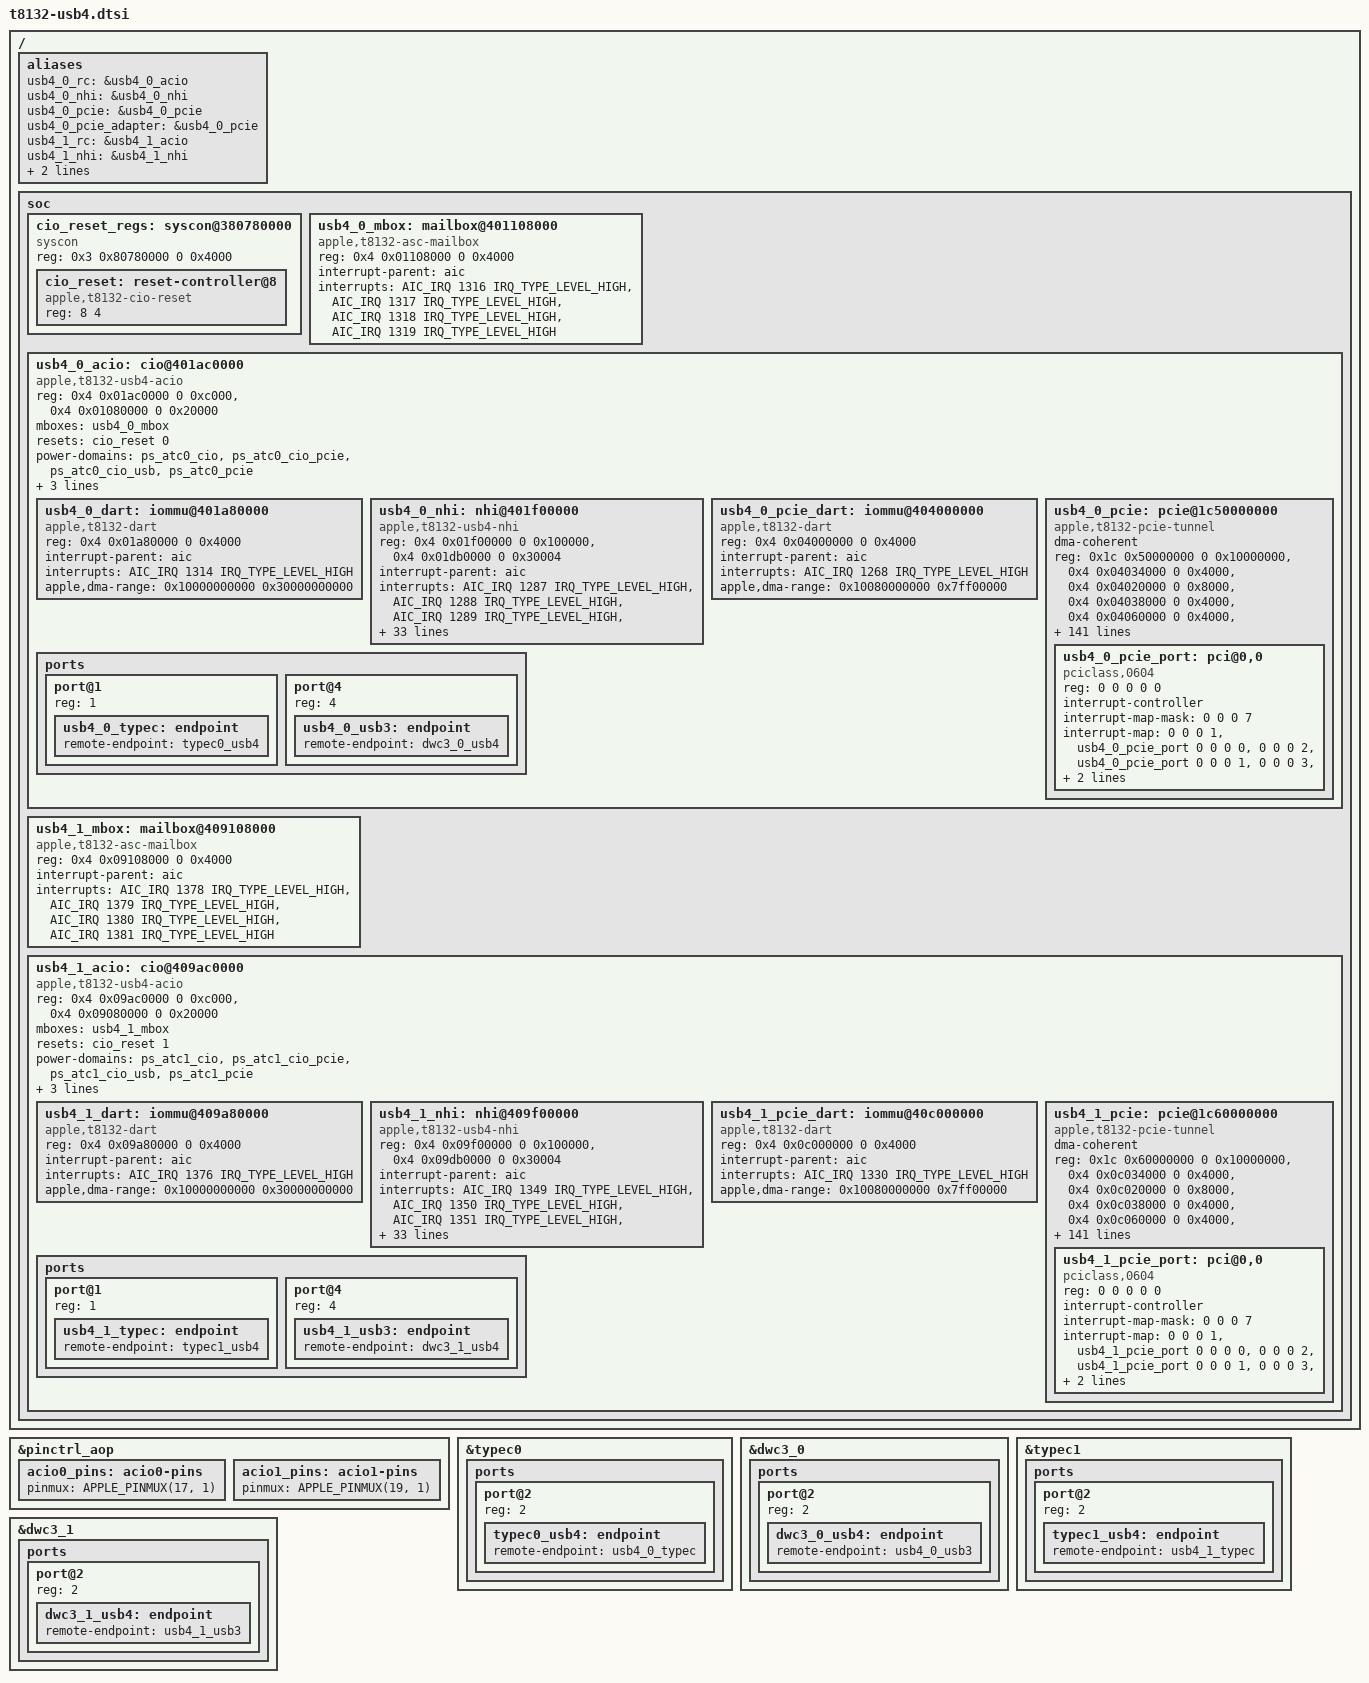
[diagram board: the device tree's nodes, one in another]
// SPDX-License-Identifier: GPL-2.0+ OR MIT
/*
 * T8132 USB4/Thunderbolt on ACIO0 and ACIO1, the Type-C ports that J713 and J773g share.
 * Resources from the J773g and J713 ADTs, which agree for both controllers.
 */
/ {
	aliases {
		usb4_0_rc = &usb4_0_acio;
		usb4_0_nhi = &usb4_0_nhi;
		usb4_0_pcie = &usb4_0_pcie;
		usb4_0_pcie_adapter = &usb4_0_pcie;
		usb4_1_rc = &usb4_1_acio;
		usb4_1_nhi = &usb4_1_nhi;
		usb4_1_pcie = &usb4_1_pcie;
		usb4_1_pcie_adapter = &usb4_1_pcie;
	};
	soc {
		cio_reset_regs: syscon@380780000 {
			compatible = "syscon", "simple-mfd";
			reg = <0x3 0x80780000 0 0x4000>;
			#address-cells = <1>;
			#size-cells = <1>;
			cio_reset: reset-controller@8 {
				compatible = "apple,t8132-cio-reset", "apple,t6000-cio-reset";
				reg = <8 4>;
				#reset-cells = <1>;
			};
		};
		usb4_0_mbox: mailbox@401108000 {
			compatible = "apple,t8132-asc-mailbox", "apple,asc-mailbox-v4";
			reg = <0x4 0x01108000 0 0x4000>;
			interrupt-parent = <&aic>;
			/* ADT orders each pair as not-empty, empty. */
			interrupts = <AIC_IRQ 1316 IRQ_TYPE_LEVEL_HIGH>,
				     <AIC_IRQ 1317 IRQ_TYPE_LEVEL_HIGH>,
				     <AIC_IRQ 1318 IRQ_TYPE_LEVEL_HIGH>,
				     <AIC_IRQ 1319 IRQ_TYPE_LEVEL_HIGH>;
			interrupt-names = "send-empty",
				"send-not-empty",
				"recv-empty",
				"recv-not-empty";
			#mbox-cells = <0>;
		};
		usb4_0_acio: cio@401ac0000 {
			compatible = "apple,t8132-usb4-acio", "apple,t8103-usb4-acio";
			reg = <0x4 0x01ac0000 0 0xc000>, <0x4 0x01080000 0 0x20000>;
			reg-names = "rc", "sram";
			mboxes = <&usb4_0_mbox>;
			resets = <&cio_reset 0>;
			power-domains = <&ps_atc0_cio>, <&ps_atc0_cio_pcie>,
					<&ps_atc0_cio_usb>, <&ps_atc0_pcie>;
			/* The port controller hands over USB4/TBT mode and cable details. */
			thunderbolt-switch;
			pinctrl-0 = <&acio0_pins>;
			pinctrl-names = "default";
			/* PCIe windows lie outside ACIO's local register aperture. */
			#address-cells = <2>;
			#size-cells = <2>;
			ranges;
			nonposted-mmio;
			usb4_0_dart: iommu@401a80000 {
				compatible = "apple,t8132-dart", "apple,t8110-dart";
				reg = <0x4 0x01a80000 0 0x4000>;
				interrupt-parent = <&aic>;
				interrupts = <AIC_IRQ 1314 IRQ_TYPE_LEVEL_HIGH>;
				#iommu-cells = <1>;
				apple,dma-range = /bits/ 64 <0x10000000000 0x30000000000>;
			};
			usb4_0_nhi: nhi@401f00000 {
				compatible = "apple,t8132-usb4-nhi", "apple,t8103-usb4-nhi";
				reg = <0x4 0x01f00000 0 0x100000>,
				      <0x4 0x01db0000 0 0x30004>;
				reg-names = "nhi", "pdf";
				interrupt-parent = <&aic>;
				interrupts = <AIC_IRQ 1287 IRQ_TYPE_LEVEL_HIGH>,
					<AIC_IRQ 1288 IRQ_TYPE_LEVEL_HIGH>,
					<AIC_IRQ 1289 IRQ_TYPE_LEVEL_HIGH>,
					<AIC_IRQ 1290 IRQ_TYPE_LEVEL_HIGH>,
					<AIC_IRQ 1291 IRQ_TYPE_LEVEL_HIGH>,
					<AIC_IRQ 1292 IRQ_TYPE_LEVEL_HIGH>,
					<AIC_IRQ 1293 IRQ_TYPE_LEVEL_HIGH>,
					<AIC_IRQ 1294 IRQ_TYPE_LEVEL_HIGH>,
					<AIC_IRQ 1295 IRQ_TYPE_LEVEL_HIGH>,
					<AIC_IRQ 1296 IRQ_TYPE_LEVEL_HIGH>,
					<AIC_IRQ 1297 IRQ_TYPE_LEVEL_HIGH>,
					<AIC_IRQ 1298 IRQ_TYPE_LEVEL_HIGH>,
					<AIC_IRQ 1299 IRQ_TYPE_LEVEL_HIGH>,
					<AIC_IRQ 1300 IRQ_TYPE_LEVEL_HIGH>,
					<AIC_IRQ 1301 IRQ_TYPE_LEVEL_HIGH>,
					<AIC_IRQ 1302 IRQ_TYPE_LEVEL_HIGH>,
					<AIC_IRQ 1303 IRQ_TYPE_LEVEL_HIGH>,
					<AIC_IRQ 1304 IRQ_TYPE_LEVEL_HIGH>,
					<AIC_IRQ 1305 IRQ_TYPE_LEVEL_HIGH>,
					<AIC_IRQ 1306 IRQ_TYPE_LEVEL_HIGH>,
					<AIC_IRQ 1307 IRQ_TYPE_LEVEL_HIGH>,
					<AIC_IRQ 1308 IRQ_TYPE_LEVEL_HIGH>,
					<AIC_IRQ 1309 IRQ_TYPE_LEVEL_HIGH>,
					<AIC_IRQ 1310 IRQ_TYPE_LEVEL_HIGH>;
				interrupt-names = "txring0",
					"txring1",
					"txring2",
					"txring3",
					"txring4",
					"txring5",
					"txring6",
					"txring7",
					"txring8",
					"txring9",
					"txring10",
					"txring11",
					"rxring0",
					"rxring1",
					"rxring2",
					"rxring3",
					"rxring4",
					"rxring5",
					"rxring6",
					"rxring7",
					"rxring8",
					"rxring9",
					"rxring10",
					"rxring11";
				/* T8132 has a DART stream for each TX and RX ring. */
				iommus = <&usb4_0_dart 0>,
				<&usb4_0_dart 1>,
				<&usb4_0_dart 2>,
				<&usb4_0_dart 3>,
				<&usb4_0_dart 4>,
				<&usb4_0_dart 5>,
				<&usb4_0_dart 6>,
				<&usb4_0_dart 7>,
				<&usb4_0_dart 8>,
				<&usb4_0_dart 9>,
				<&usb4_0_dart 10>,
				<&usb4_0_dart 11>,
				<&usb4_0_dart 16>,
				<&usb4_0_dart 17>,
				<&usb4_0_dart 18>,
				<&usb4_0_dart 19>,
				<&usb4_0_dart 20>,
				<&usb4_0_dart 21>,
				<&usb4_0_dart 22>,
				<&usb4_0_dart 23>,
				<&usb4_0_dart 24>,
				<&usb4_0_dart 25>,
				<&usb4_0_dart 26>,
				<&usb4_0_dart 27>;
				apple,thunderbolt-drom = [00];
			};
			usb4_0_pcie_dart: iommu@404000000 {
				compatible = "apple,t8132-dart", "apple,t8110-dart";
				reg = <0x4 0x04000000 0 0x4000>;
				interrupt-parent = <&aic>;
				interrupts = <AIC_IRQ 1268 IRQ_TYPE_LEVEL_HIGH>;
				#iommu-cells = <1>;
				apple,dma-range = /bits/ 64 <0x10080000000 0x7ff00000>;
			};
			usb4_0_pcie: pcie@1c50000000 {
				compatible = "apple,t8132-pcie-tunnel";
				dma-coherent;
				device_type = "pci";
				reg = <0x1c 0x50000000 0 0x10000000>,
				      <0x4 0x04034000 0 0x4000>,
				      <0x4 0x04020000 0 0x8000>,
				      <0x4 0x04038000 0 0x4000>,
				      <0x4 0x04060000 0 0x4000>,
				      <0x4 0x01e44000 0 0x4000>,
				      <0x4 0x0402c000 0 0x4000>,
				      <0x4 0x04028000 0 0x4000>;
				reg-names = "config",
					"rc",
					"port0",
					"fabric",
					"debug",
					"adapter",
					"ltssm",
					"intr2axi";
				interrupt-parent = <&aic>;
				interrupts = <AIC_IRQ 1267 IRQ_TYPE_LEVEL_HIGH>;
				msi-controller;
				msi-parent = <&usb4_0_pcie>;
				msi-ranges = <&aic AIC_IRQ 1570 IRQ_TYPE_EDGE_RISING 32>;
				apple,msi-vector-base = <64>;
				/*
				 * Give each PCI bus its own DART stream. Keep functions on
				 * the same bus together, as on the other Apple PCIe hosts.
				 * Cover the full bus-range so hotplug bus renumbering does
				 * not alias unrelated buses. PCI ACS and DMA aliases still
				 * determine which streams may use independent domains.
				 */
				iommu-map-mask = <0xff00>;
				iommu-map = <0x0000 &usb4_0_pcie_dart 0 1>,
					    <0x0100 &usb4_0_pcie_dart 1 1>,
					    <0x0200 &usb4_0_pcie_dart 2 1>,
					    <0x0300 &usb4_0_pcie_dart 3 1>,
					    <0x0400 &usb4_0_pcie_dart 4 1>,
					    <0x0500 &usb4_0_pcie_dart 5 1>,
					    <0x0600 &usb4_0_pcie_dart 6 1>,
					    <0x0700 &usb4_0_pcie_dart 7 1>,
					    <0x0800 &usb4_0_pcie_dart 8 1>,
					    <0x0900 &usb4_0_pcie_dart 9 1>,
					    <0x0a00 &usb4_0_pcie_dart 10 1>,
					    <0x0b00 &usb4_0_pcie_dart 11 1>,
					    <0x0c00 &usb4_0_pcie_dart 12 1>,
					    <0x0d00 &usb4_0_pcie_dart 13 1>,
					    <0x0e00 &usb4_0_pcie_dart 14 1>,
					    <0x0f00 &usb4_0_pcie_dart 15 1>,
					    <0x1000 &usb4_0_pcie_dart 16 1>,
					    <0x1100 &usb4_0_pcie_dart 17 1>,
					    <0x1200 &usb4_0_pcie_dart 18 1>,
					    <0x1300 &usb4_0_pcie_dart 19 1>,
					    <0x1400 &usb4_0_pcie_dart 20 1>,
					    <0x1500 &usb4_0_pcie_dart 21 1>,
					    <0x1600 &usb4_0_pcie_dart 22 1>,
					    <0x1700 &usb4_0_pcie_dart 23 1>,
					    <0x1800 &usb4_0_pcie_dart 24 1>,
					    <0x1900 &usb4_0_pcie_dart 25 1>,
					    <0x1a00 &usb4_0_pcie_dart 26 1>,
					    <0x1b00 &usb4_0_pcie_dart 27 1>,
					    <0x1c00 &usb4_0_pcie_dart 28 1>,
					    <0x1d00 &usb4_0_pcie_dart 29 1>,
					    <0x1e00 &usb4_0_pcie_dart 30 1>,
					    <0x1f00 &usb4_0_pcie_dart 31 1>,
					    <0x2000 &usb4_0_pcie_dart 32 1>,
					    <0x2100 &usb4_0_pcie_dart 33 1>,
					    <0x2200 &usb4_0_pcie_dart 34 1>,
					    <0x2300 &usb4_0_pcie_dart 35 1>,
					    <0x2400 &usb4_0_pcie_dart 36 1>,
					    <0x2500 &usb4_0_pcie_dart 37 1>,
					    <0x2600 &usb4_0_pcie_dart 38 1>,
					    <0x2700 &usb4_0_pcie_dart 39 1>,
					    <0x2800 &usb4_0_pcie_dart 40 1>,
					    <0x2900 &usb4_0_pcie_dart 41 1>,
					    <0x2a00 &usb4_0_pcie_dart 42 1>,
					    <0x2b00 &usb4_0_pcie_dart 43 1>,
					    <0x2c00 &usb4_0_pcie_dart 44 1>,
					    <0x2d00 &usb4_0_pcie_dart 45 1>,
					    <0x2e00 &usb4_0_pcie_dart 46 1>,
					    <0x2f00 &usb4_0_pcie_dart 47 1>,
					    <0x3000 &usb4_0_pcie_dart 48 1>,
					    <0x3100 &usb4_0_pcie_dart 49 1>,
					    <0x3200 &usb4_0_pcie_dart 50 1>,
					    <0x3300 &usb4_0_pcie_dart 51 1>,
					    <0x3400 &usb4_0_pcie_dart 52 1>,
					    <0x3500 &usb4_0_pcie_dart 53 1>,
					    <0x3600 &usb4_0_pcie_dart 54 1>,
					    <0x3700 &usb4_0_pcie_dart 55 1>,
					    <0x3800 &usb4_0_pcie_dart 56 1>,
					    <0x3900 &usb4_0_pcie_dart 57 1>,
					    <0x3a00 &usb4_0_pcie_dart 58 1>,
					    <0x3b00 &usb4_0_pcie_dart 59 1>,
					    <0x3c00 &usb4_0_pcie_dart 60 1>,
					    <0x3d00 &usb4_0_pcie_dart 61 1>,
					    <0x3e00 &usb4_0_pcie_dart 62 1>,
					    <0x3f00 &usb4_0_pcie_dart 63 1>,
					    <0x4000 &usb4_0_pcie_dart 64 1>,
					    <0x4100 &usb4_0_pcie_dart 65 1>,
					    <0x4200 &usb4_0_pcie_dart 66 1>,
					    <0x4300 &usb4_0_pcie_dart 67 1>,
					    <0x4400 &usb4_0_pcie_dart 68 1>,
					    <0x4500 &usb4_0_pcie_dart 69 1>,
					    <0x4600 &usb4_0_pcie_dart 70 1>,
					    <0x4700 &usb4_0_pcie_dart 71 1>,
					    <0x4800 &usb4_0_pcie_dart 72 1>,
					    <0x4900 &usb4_0_pcie_dart 73 1>,
					    <0x4a00 &usb4_0_pcie_dart 74 1>,
					    <0x4b00 &usb4_0_pcie_dart 75 1>,
					    <0x4c00 &usb4_0_pcie_dart 76 1>,
					    <0x4d00 &usb4_0_pcie_dart 77 1>,
					    <0x4e00 &usb4_0_pcie_dart 78 1>,
					    <0x4f00 &usb4_0_pcie_dart 79 1>,
					    <0x5000 &usb4_0_pcie_dart 80 1>,
					    <0x5100 &usb4_0_pcie_dart 81 1>,
					    <0x5200 &usb4_0_pcie_dart 82 1>,
					    <0x5300 &usb4_0_pcie_dart 83 1>,
					    <0x5400 &usb4_0_pcie_dart 84 1>,
					    <0x5500 &usb4_0_pcie_dart 85 1>,
					    <0x5600 &usb4_0_pcie_dart 86 1>,
					    <0x5700 &usb4_0_pcie_dart 87 1>,
					    <0x5800 &usb4_0_pcie_dart 88 1>,
					    <0x5900 &usb4_0_pcie_dart 89 1>,
					    <0x5a00 &usb4_0_pcie_dart 90 1>,
					    <0x5b00 &usb4_0_pcie_dart 91 1>,
					    <0x5c00 &usb4_0_pcie_dart 92 1>,
					    <0x5d00 &usb4_0_pcie_dart 93 1>,
					    <0x5e00 &usb4_0_pcie_dart 94 1>,
					    <0x5f00 &usb4_0_pcie_dart 95 1>,
					    <0x6000 &usb4_0_pcie_dart 96 1>,
					    <0x6100 &usb4_0_pcie_dart 97 1>,
					    <0x6200 &usb4_0_pcie_dart 98 1>,
					    <0x6300 &usb4_0_pcie_dart 99 1>,
					    <0x6400 &usb4_0_pcie_dart 100 1>,
					    <0x6500 &usb4_0_pcie_dart 101 1>,
					    <0x6600 &usb4_0_pcie_dart 102 1>,
					    <0x6700 &usb4_0_pcie_dart 103 1>,
					    <0x6800 &usb4_0_pcie_dart 104 1>,
					    <0x6900 &usb4_0_pcie_dart 105 1>,
					    <0x6a00 &usb4_0_pcie_dart 106 1>,
					    <0x6b00 &usb4_0_pcie_dart 107 1>,
					    <0x6c00 &usb4_0_pcie_dart 108 1>,
					    <0x6d00 &usb4_0_pcie_dart 109 1>,
					    <0x6e00 &usb4_0_pcie_dart 110 1>,
					    <0x6f00 &usb4_0_pcie_dart 111 1>,
					    <0x7000 &usb4_0_pcie_dart 112 1>,
					    <0x7100 &usb4_0_pcie_dart 113 1>,
					    <0x7200 &usb4_0_pcie_dart 114 1>,
					    <0x7300 &usb4_0_pcie_dart 115 1>,
					    <0x7400 &usb4_0_pcie_dart 116 1>,
					    <0x7500 &usb4_0_pcie_dart 117 1>,
					    <0x7600 &usb4_0_pcie_dart 118 1>,
					    <0x7700 &usb4_0_pcie_dart 119 1>,
					    <0x7800 &usb4_0_pcie_dart 120 1>,
					    <0x7900 &usb4_0_pcie_dart 121 1>,
					    <0x7a00 &usb4_0_pcie_dart 122 1>,
					    <0x7b00 &usb4_0_pcie_dart 123 1>,
					    <0x7c00 &usb4_0_pcie_dart 124 1>,
					    <0x7d00 &usb4_0_pcie_dart 125 1>,
					    <0x7e00 &usb4_0_pcie_dart 126 1>,
					    <0x7f00 &usb4_0_pcie_dart 127 1>;
				linux,pci-domain = <1>;
				bus-range = <0 127>;
				#address-cells = <3>;
				#size-cells = <2>;
				ranges = <0x43000000 0x8 0 0x8 0 0x2 0>,
					 <0x02000000 0 0x100000 0xa 0x00100000 0 0x3ff00000>;
				usb4_0_pcie_port: pci@0,0 {
					compatible = "pciclass,0604";
					device_type = "pci";
					reg = <0 0 0 0 0>;
					#address-cells = <3>;
					#size-cells = <2>;
					ranges;
					interrupt-controller;
					#interrupt-cells = <1>;
					interrupt-map-mask = <0 0 0 7>;
					interrupt-map = <0 0 0 1 &usb4_0_pcie_port 0 0 0 0>,
							<0 0 0 2 &usb4_0_pcie_port 0 0 0 1>,
							<0 0 0 3 &usb4_0_pcie_port 0 0 0 2>,
							<0 0 0 4 &usb4_0_pcie_port 0 0 0 3>;
				};
			};
			ports {
				#address-cells = <1>;
				#size-cells = <0>;
				port@1 {
					reg = <1>;
					usb4_0_typec: endpoint { remote-endpoint = <&typec0_usb4>; };
				};
				port@4 {
					reg = <4>;
					usb4_0_usb3: endpoint { remote-endpoint = <&dwc3_0_usb4>; };
				};
			};
		};
		usb4_1_mbox: mailbox@409108000 {
			compatible = "apple,t8132-asc-mailbox", "apple,asc-mailbox-v4";
			reg = <0x4 0x09108000 0 0x4000>;
			interrupt-parent = <&aic>;
			/* ADT orders each pair as not-empty, empty. */
			interrupts = <AIC_IRQ 1378 IRQ_TYPE_LEVEL_HIGH>,
				     <AIC_IRQ 1379 IRQ_TYPE_LEVEL_HIGH>,
				     <AIC_IRQ 1380 IRQ_TYPE_LEVEL_HIGH>,
				     <AIC_IRQ 1381 IRQ_TYPE_LEVEL_HIGH>;
			interrupt-names = "send-empty",
				"send-not-empty",
				"recv-empty",
				"recv-not-empty";
			#mbox-cells = <0>;
		};
		usb4_1_acio: cio@409ac0000 {
			compatible = "apple,t8132-usb4-acio", "apple,t8103-usb4-acio";
			reg = <0x4 0x09ac0000 0 0xc000>, <0x4 0x09080000 0 0x20000>;
			reg-names = "rc", "sram";
			mboxes = <&usb4_1_mbox>;
			resets = <&cio_reset 1>;
			power-domains = <&ps_atc1_cio>, <&ps_atc1_cio_pcie>,
					<&ps_atc1_cio_usb>, <&ps_atc1_pcie>;
			/* The port controller hands over USB4/TBT mode and cable details. */
			thunderbolt-switch;
			pinctrl-0 = <&acio1_pins>;
			pinctrl-names = "default";
			/* PCIe windows lie outside ACIO's local register aperture. */
			#address-cells = <2>;
			#size-cells = <2>;
			ranges;
			nonposted-mmio;
			usb4_1_dart: iommu@409a80000 {
				compatible = "apple,t8132-dart", "apple,t8110-dart";
				reg = <0x4 0x09a80000 0 0x4000>;
				interrupt-parent = <&aic>;
				interrupts = <AIC_IRQ 1376 IRQ_TYPE_LEVEL_HIGH>;
				#iommu-cells = <1>;
				apple,dma-range = /bits/ 64 <0x10000000000 0x30000000000>;
			};
			usb4_1_nhi: nhi@409f00000 {
				compatible = "apple,t8132-usb4-nhi", "apple,t8103-usb4-nhi";
				reg = <0x4 0x09f00000 0 0x100000>,
				      <0x4 0x09db0000 0 0x30004>;
				reg-names = "nhi", "pdf";
				interrupt-parent = <&aic>;
				interrupts = <AIC_IRQ 1349 IRQ_TYPE_LEVEL_HIGH>,
					<AIC_IRQ 1350 IRQ_TYPE_LEVEL_HIGH>,
					<AIC_IRQ 1351 IRQ_TYPE_LEVEL_HIGH>,
					<AIC_IRQ 1352 IRQ_TYPE_LEVEL_HIGH>,
					<AIC_IRQ 1353 IRQ_TYPE_LEVEL_HIGH>,
					<AIC_IRQ 1354 IRQ_TYPE_LEVEL_HIGH>,
					<AIC_IRQ 1355 IRQ_TYPE_LEVEL_HIGH>,
					<AIC_IRQ 1356 IRQ_TYPE_LEVEL_HIGH>,
					<AIC_IRQ 1357 IRQ_TYPE_LEVEL_HIGH>,
					<AIC_IRQ 1358 IRQ_TYPE_LEVEL_HIGH>,
					<AIC_IRQ 1359 IRQ_TYPE_LEVEL_HIGH>,
					<AIC_IRQ 1360 IRQ_TYPE_LEVEL_HIGH>,
					<AIC_IRQ 1361 IRQ_TYPE_LEVEL_HIGH>,
					<AIC_IRQ 1362 IRQ_TYPE_LEVEL_HIGH>,
					<AIC_IRQ 1363 IRQ_TYPE_LEVEL_HIGH>,
					<AIC_IRQ 1364 IRQ_TYPE_LEVEL_HIGH>,
					<AIC_IRQ 1365 IRQ_TYPE_LEVEL_HIGH>,
					<AIC_IRQ 1366 IRQ_TYPE_LEVEL_HIGH>,
					<AIC_IRQ 1367 IRQ_TYPE_LEVEL_HIGH>,
					<AIC_IRQ 1368 IRQ_TYPE_LEVEL_HIGH>,
					<AIC_IRQ 1369 IRQ_TYPE_LEVEL_HIGH>,
					<AIC_IRQ 1370 IRQ_TYPE_LEVEL_HIGH>,
					<AIC_IRQ 1371 IRQ_TYPE_LEVEL_HIGH>,
					<AIC_IRQ 1372 IRQ_TYPE_LEVEL_HIGH>;
				interrupt-names = "txring0",
					"txring1",
					"txring2",
					"txring3",
					"txring4",
					"txring5",
					"txring6",
					"txring7",
					"txring8",
					"txring9",
					"txring10",
					"txring11",
					"rxring0",
					"rxring1",
					"rxring2",
					"rxring3",
					"rxring4",
					"rxring5",
					"rxring6",
					"rxring7",
					"rxring8",
					"rxring9",
					"rxring10",
					"rxring11";
				/* T8132 has a DART stream for each TX and RX ring. */
				iommus = <&usb4_1_dart 0>,
				<&usb4_1_dart 1>,
				<&usb4_1_dart 2>,
				<&usb4_1_dart 3>,
				<&usb4_1_dart 4>,
				<&usb4_1_dart 5>,
				<&usb4_1_dart 6>,
				<&usb4_1_dart 7>,
				<&usb4_1_dart 8>,
				<&usb4_1_dart 9>,
				<&usb4_1_dart 10>,
				<&usb4_1_dart 11>,
				<&usb4_1_dart 16>,
				<&usb4_1_dart 17>,
				<&usb4_1_dart 18>,
				<&usb4_1_dart 19>,
				<&usb4_1_dart 20>,
				<&usb4_1_dart 21>,
				<&usb4_1_dart 22>,
				<&usb4_1_dart 23>,
				<&usb4_1_dart 24>,
				<&usb4_1_dart 25>,
				<&usb4_1_dart 26>,
				<&usb4_1_dart 27>;
				apple,thunderbolt-drom = [00];
			};
			usb4_1_pcie_dart: iommu@40c000000 {
				compatible = "apple,t8132-dart", "apple,t8110-dart";
				reg = <0x4 0x0c000000 0 0x4000>;
				interrupt-parent = <&aic>;
				interrupts = <AIC_IRQ 1330 IRQ_TYPE_LEVEL_HIGH>;
				#iommu-cells = <1>;
				apple,dma-range = /bits/ 64 <0x10080000000 0x7ff00000>;
			};
			usb4_1_pcie: pcie@1c60000000 {
				compatible = "apple,t8132-pcie-tunnel";
				dma-coherent;
				device_type = "pci";
				reg = <0x1c 0x60000000 0 0x10000000>,
				      <0x4 0x0c034000 0 0x4000>,
				      <0x4 0x0c020000 0 0x8000>,
				      <0x4 0x0c038000 0 0x4000>,
				      <0x4 0x0c060000 0 0x4000>,
				      <0x4 0x09e44000 0 0x4000>,
				      <0x4 0x0c02c000 0 0x4000>,
				      <0x4 0x0c028000 0 0x4000>;
				reg-names = "config",
					"rc",
					"port0",
					"fabric",
					"debug",
					"adapter",
					"ltssm",
					"intr2axi";
				interrupt-parent = <&aic>;
				interrupts = <AIC_IRQ 1329 IRQ_TYPE_LEVEL_HIGH>;
				msi-controller;
				msi-parent = <&usb4_1_pcie>;
				msi-ranges = <&aic AIC_IRQ 1634 IRQ_TYPE_EDGE_RISING 32>;
				apple,msi-vector-base = <128>;
				/*
				 * Give each PCI bus its own DART stream. Keep functions on
				 * the same bus together, as on the other Apple PCIe hosts.
				 * Cover the full bus-range so hotplug bus renumbering does
				 * not alias unrelated buses. PCI ACS and DMA aliases still
				 * determine which streams may use independent domains.
				 */
				iommu-map-mask = <0xff00>;
				iommu-map = <0x0000 &usb4_1_pcie_dart 0 1>,
					    <0x0100 &usb4_1_pcie_dart 1 1>,
					    <0x0200 &usb4_1_pcie_dart 2 1>,
					    <0x0300 &usb4_1_pcie_dart 3 1>,
					    <0x0400 &usb4_1_pcie_dart 4 1>,
					    <0x0500 &usb4_1_pcie_dart 5 1>,
					    <0x0600 &usb4_1_pcie_dart 6 1>,
					    <0x0700 &usb4_1_pcie_dart 7 1>,
					    <0x0800 &usb4_1_pcie_dart 8 1>,
					    <0x0900 &usb4_1_pcie_dart 9 1>,
					    <0x0a00 &usb4_1_pcie_dart 10 1>,
					    <0x0b00 &usb4_1_pcie_dart 11 1>,
					    <0x0c00 &usb4_1_pcie_dart 12 1>,
					    <0x0d00 &usb4_1_pcie_dart 13 1>,
					    <0x0e00 &usb4_1_pcie_dart 14 1>,
					    <0x0f00 &usb4_1_pcie_dart 15 1>,
					    <0x1000 &usb4_1_pcie_dart 16 1>,
					    <0x1100 &usb4_1_pcie_dart 17 1>,
					    <0x1200 &usb4_1_pcie_dart 18 1>,
					    <0x1300 &usb4_1_pcie_dart 19 1>,
					    <0x1400 &usb4_1_pcie_dart 20 1>,
					    <0x1500 &usb4_1_pcie_dart 21 1>,
					    <0x1600 &usb4_1_pcie_dart 22 1>,
					    <0x1700 &usb4_1_pcie_dart 23 1>,
					    <0x1800 &usb4_1_pcie_dart 24 1>,
					    <0x1900 &usb4_1_pcie_dart 25 1>,
					    <0x1a00 &usb4_1_pcie_dart 26 1>,
					    <0x1b00 &usb4_1_pcie_dart 27 1>,
					    <0x1c00 &usb4_1_pcie_dart 28 1>,
					    <0x1d00 &usb4_1_pcie_dart 29 1>,
					    <0x1e00 &usb4_1_pcie_dart 30 1>,
					    <0x1f00 &usb4_1_pcie_dart 31 1>,
					    <0x2000 &usb4_1_pcie_dart 32 1>,
					    <0x2100 &usb4_1_pcie_dart 33 1>,
					    <0x2200 &usb4_1_pcie_dart 34 1>,
					    <0x2300 &usb4_1_pcie_dart 35 1>,
					    <0x2400 &usb4_1_pcie_dart 36 1>,
					    <0x2500 &usb4_1_pcie_dart 37 1>,
					    <0x2600 &usb4_1_pcie_dart 38 1>,
					    <0x2700 &usb4_1_pcie_dart 39 1>,
					    <0x2800 &usb4_1_pcie_dart 40 1>,
					    <0x2900 &usb4_1_pcie_dart 41 1>,
					    <0x2a00 &usb4_1_pcie_dart 42 1>,
					    <0x2b00 &usb4_1_pcie_dart 43 1>,
					    <0x2c00 &usb4_1_pcie_dart 44 1>,
					    <0x2d00 &usb4_1_pcie_dart 45 1>,
					    <0x2e00 &usb4_1_pcie_dart 46 1>,
					    <0x2f00 &usb4_1_pcie_dart 47 1>,
					    <0x3000 &usb4_1_pcie_dart 48 1>,
					    <0x3100 &usb4_1_pcie_dart 49 1>,
					    <0x3200 &usb4_1_pcie_dart 50 1>,
					    <0x3300 &usb4_1_pcie_dart 51 1>,
					    <0x3400 &usb4_1_pcie_dart 52 1>,
					    <0x3500 &usb4_1_pcie_dart 53 1>,
					    <0x3600 &usb4_1_pcie_dart 54 1>,
					    <0x3700 &usb4_1_pcie_dart 55 1>,
					    <0x3800 &usb4_1_pcie_dart 56 1>,
					    <0x3900 &usb4_1_pcie_dart 57 1>,
					    <0x3a00 &usb4_1_pcie_dart 58 1>,
					    <0x3b00 &usb4_1_pcie_dart 59 1>,
					    <0x3c00 &usb4_1_pcie_dart 60 1>,
					    <0x3d00 &usb4_1_pcie_dart 61 1>,
					    <0x3e00 &usb4_1_pcie_dart 62 1>,
					    <0x3f00 &usb4_1_pcie_dart 63 1>,
					    <0x4000 &usb4_1_pcie_dart 64 1>,
					    <0x4100 &usb4_1_pcie_dart 65 1>,
					    <0x4200 &usb4_1_pcie_dart 66 1>,
					    <0x4300 &usb4_1_pcie_dart 67 1>,
					    <0x4400 &usb4_1_pcie_dart 68 1>,
					    <0x4500 &usb4_1_pcie_dart 69 1>,
					    <0x4600 &usb4_1_pcie_dart 70 1>,
					    <0x4700 &usb4_1_pcie_dart 71 1>,
					    <0x4800 &usb4_1_pcie_dart 72 1>,
					    <0x4900 &usb4_1_pcie_dart 73 1>,
					    <0x4a00 &usb4_1_pcie_dart 74 1>,
					    <0x4b00 &usb4_1_pcie_dart 75 1>,
					    <0x4c00 &usb4_1_pcie_dart 76 1>,
					    <0x4d00 &usb4_1_pcie_dart 77 1>,
					    <0x4e00 &usb4_1_pcie_dart 78 1>,
					    <0x4f00 &usb4_1_pcie_dart 79 1>,
					    <0x5000 &usb4_1_pcie_dart 80 1>,
					    <0x5100 &usb4_1_pcie_dart 81 1>,
					    <0x5200 &usb4_1_pcie_dart 82 1>,
					    <0x5300 &usb4_1_pcie_dart 83 1>,
					    <0x5400 &usb4_1_pcie_dart 84 1>,
					    <0x5500 &usb4_1_pcie_dart 85 1>,
					    <0x5600 &usb4_1_pcie_dart 86 1>,
					    <0x5700 &usb4_1_pcie_dart 87 1>,
					    <0x5800 &usb4_1_pcie_dart 88 1>,
					    <0x5900 &usb4_1_pcie_dart 89 1>,
					    <0x5a00 &usb4_1_pcie_dart 90 1>,
					    <0x5b00 &usb4_1_pcie_dart 91 1>,
					    <0x5c00 &usb4_1_pcie_dart 92 1>,
					    <0x5d00 &usb4_1_pcie_dart 93 1>,
					    <0x5e00 &usb4_1_pcie_dart 94 1>,
					    <0x5f00 &usb4_1_pcie_dart 95 1>,
					    <0x6000 &usb4_1_pcie_dart 96 1>,
					    <0x6100 &usb4_1_pcie_dart 97 1>,
					    <0x6200 &usb4_1_pcie_dart 98 1>,
					    <0x6300 &usb4_1_pcie_dart 99 1>,
					    <0x6400 &usb4_1_pcie_dart 100 1>,
					    <0x6500 &usb4_1_pcie_dart 101 1>,
					    <0x6600 &usb4_1_pcie_dart 102 1>,
					    <0x6700 &usb4_1_pcie_dart 103 1>,
					    <0x6800 &usb4_1_pcie_dart 104 1>,
					    <0x6900 &usb4_1_pcie_dart 105 1>,
					    <0x6a00 &usb4_1_pcie_dart 106 1>,
					    <0x6b00 &usb4_1_pcie_dart 107 1>,
					    <0x6c00 &usb4_1_pcie_dart 108 1>,
					    <0x6d00 &usb4_1_pcie_dart 109 1>,
					    <0x6e00 &usb4_1_pcie_dart 110 1>,
					    <0x6f00 &usb4_1_pcie_dart 111 1>,
					    <0x7000 &usb4_1_pcie_dart 112 1>,
					    <0x7100 &usb4_1_pcie_dart 113 1>,
					    <0x7200 &usb4_1_pcie_dart 114 1>,
					    <0x7300 &usb4_1_pcie_dart 115 1>,
					    <0x7400 &usb4_1_pcie_dart 116 1>,
					    <0x7500 &usb4_1_pcie_dart 117 1>,
					    <0x7600 &usb4_1_pcie_dart 118 1>,
					    <0x7700 &usb4_1_pcie_dart 119 1>,
					    <0x7800 &usb4_1_pcie_dart 120 1>,
					    <0x7900 &usb4_1_pcie_dart 121 1>,
					    <0x7a00 &usb4_1_pcie_dart 122 1>,
					    <0x7b00 &usb4_1_pcie_dart 123 1>,
					    <0x7c00 &usb4_1_pcie_dart 124 1>,
					    <0x7d00 &usb4_1_pcie_dart 125 1>,
					    <0x7e00 &usb4_1_pcie_dart 126 1>,
					    <0x7f00 &usb4_1_pcie_dart 127 1>;
				linux,pci-domain = <2>;
				bus-range = <0 127>;
				#address-cells = <3>;
				#size-cells = <2>;
				ranges = <0x43000000 0xc 0 0xc 0 0x2 0>,
					 <0x02000000 0 0x100000 0xe 0x00100000 0 0x3ff00000>;
				usb4_1_pcie_port: pci@0,0 {
					compatible = "pciclass,0604";
					device_type = "pci";
					reg = <0 0 0 0 0>;
					#address-cells = <3>;
					#size-cells = <2>;
					ranges;
					interrupt-controller;
					#interrupt-cells = <1>;
					interrupt-map-mask = <0 0 0 7>;
					interrupt-map = <0 0 0 1 &usb4_1_pcie_port 0 0 0 0>,
							<0 0 0 2 &usb4_1_pcie_port 0 0 0 1>,
							<0 0 0 3 &usb4_1_pcie_port 0 0 0 2>,
							<0 0 0 4 &usb4_1_pcie_port 0 0 0 3>;
				};
			};
			ports {
				#address-cells = <1>;
				#size-cells = <0>;
				port@1 {
					reg = <1>;
					usb4_1_typec: endpoint { remote-endpoint = <&typec1_usb4>; };
				};
				port@4 {
					reg = <4>;
					usb4_1_usb3: endpoint { remote-endpoint = <&dwc3_1_usb4>; };
				};
			};
		};
	};
};
&pinctrl_aop {
	acio0_pins: acio0-pins { pinmux = <APPLE_PINMUX(17, 1)>; };
};
&typec0 {
	ports {
		port@2 {
			reg = <2>;
			typec0_usb4: endpoint { remote-endpoint = <&usb4_0_typec>; };
		};
	};
};
&dwc3_0 {
	ports {
		port@2 {
			reg = <2>;
			dwc3_0_usb4: endpoint { remote-endpoint = <&usb4_0_usb3>; };
		};
	};
};
&pinctrl_aop {
	acio1_pins: acio1-pins { pinmux = <APPLE_PINMUX(19, 1)>; };
};
&typec1 {
	ports {
		port@2 {
			reg = <2>;
			typec1_usb4: endpoint { remote-endpoint = <&usb4_1_typec>; };
		};
	};
};
&dwc3_1 {
	ports {
		port@2 {
			reg = <2>;
			dwc3_1_usb4: endpoint { remote-endpoint = <&usb4_1_usb3>; };
		};
	};
};
